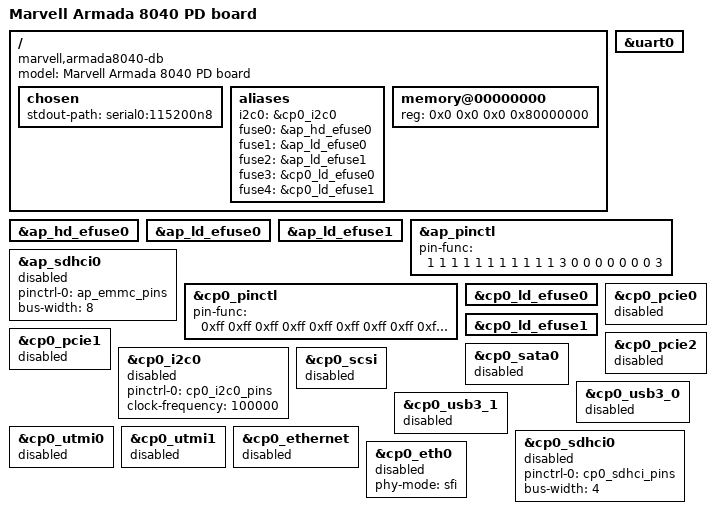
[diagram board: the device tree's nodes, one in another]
/*
 * Copyright (C) 2018 Marvell International Ltd.
 *
 * SPDX-License-Identifier:    GPL-2.0
 * https://spdx.org/licenses
 */

/*
 * Device Tree file for Marvell Armada 8040 Palladium emulation board
 */

#include "armada-80x0-db.dtsi"

/ {
	model = "Marvell Armada 8040 PD board";
	compatible = "marvell,armada8040-db", "marvell,armada8040",
		     "marvell,armada-ap806-quad", "marvell,armada-ap806";

	chosen {
		stdout-path = "serial0:115200n8";
	};

	aliases {
		i2c0 = &cp0_i2c0;
		fuse0 = &ap_hd_efuse0;
		fuse1 = &ap_ld_efuse0;
		fuse2 = &ap_ld_efuse1;
		fuse3 = &cp0_ld_efuse0;
		fuse4 = &cp0_ld_efuse1;
	};

	memory@00000000 {
		device_type = "memory";
		reg = <0x0 0x0 0x0 0x80000000>;
	};


};

/* Accessible over the mini-USB CON9 connector on the main board */
&uart0 {
	status = "okay";
};

&ap_hd_efuse0 {
	status = "okay";
};

&ap_ld_efuse0 {
	status = "okay";
};

&ap_ld_efuse1 {
	status = "okay";
};

&ap_pinctl {
	/* MPP Bus:
	 * SDIO  [0-10]
	 * UART0 [11,19]
	 */
		  /* 0 1 2 3 4 5 6 7 8 9 */
	pin-func = < 1 1 1 1 1 1 1 1 1 1
		     1 3 0 0 0 0 0 0 0 3 >;
};

&ap_sdhci0 {
	pinctrl-names = "default";
	pinctrl-0 = <&ap_emmc_pins>;
	bus-width = <8>;
	status = "disabled";
};

&cp0_pinctl {
	/* MPP Bus:
	 *	[0-31]	= 0xff: Keep default CP0_shared_pins
	 *	[11]	CLKOUT_MPP_11 (out)
	 *	[23]	LINK_RD_IN_CP2CP (in)
	 *	[25]	CLKOUT_MPP_25 (out)
	 *	[29]	AVS_FB_IN_CP2CP (in)
	 *	[32,34]	GE_MDIO/MDC
	 *	[33]	GPIO: GE_INT#/push button/Wake
	 *	[35]	MSS_GPIO[3]: MSS_PWDN
	 *	[36]	MSS_GPIO[5]: MSS_VTT_EN
	 *	[37-38]	I2C0
	 *	[39]	PTP_CLK
	 *	[40-41]	SATA[0/1]_PRESENT_ACTIVEn
	 *	[42-43]	XG_MDC/XG_MDIO (XSMI)
	 *	[44-55]	RGMII1
	 *	[56-62]	SD
	 */
	/*   0    1    2    3    4    5    6    7    8    9 */
	pin-func = < 0xff 0xff 0xff 0xff 0xff 0xff 0xff 0xff 0xff 0xff
		     0xff 0xff 0xff 0xff 0xff 0xff 0xff 0xff 0xff 0xff
		     0xff 0xff 0xff 0xff 0xff 0xff 0xff 0xff 0xff 0xff
		     0xff 0xff 0x7  0x0  0x7  0xa  0xa  0x2  0x2  0x5
		     0x9  0x9  0x8  0x8  0x1  0x1  0x1  0x1  0x1  0x1
		     0x1  0x1  0x1  0x1  0x1  0x1  0xe  0xe  0xe  0xe
		     0xe  0xe  0xe>;
};

&cp0_ld_efuse0 {
	status = "okay";
};

&cp0_ld_efuse1 {
	status = "okay";
};


/* CON6 on CP0 expansion */
&cp0_pcie0 {
	status = "disabled";
};

&cp0_pcie1 {
	status = "disabled";
};

/* CON5 on CP0 expansion */
&cp0_pcie2 {
	status = "disabled";
};

&cp0_i2c0 {
	pinctrl-names = "default";
	pinctrl-0 = <&cp0_i2c0_pins>;
	status = "disabled";
	clock-frequency = <100000>;
};

/* CON4 on CP0 expansion */
&cp0_sata0 {
	status = "disabled";
};

&cp0_scsi {
	status = "disabled";
};

/* CON9 on CP0 expansion */
&cp0_usb3_0 {
	status = "disabled";
};

/* CON10 on CP0 expansion */
&cp0_usb3_1 {
	status = "disabled";
};

&cp0_utmi0 {
	status = "disabled";
};

&cp0_utmi1 {
	status = "disabled";
};

&cp0_sdhci0 {
	pinctrl-names = "default";
	pinctrl-0 = <&cp0_sdhci_pins>;
	bus-width = <4>;
	status = "disabled";
};

&cp0_ethernet {
	status = "disabled";
};


&cp0_eth0 {
        status = "disabled";
        phy-mode = "sfi"; /* lane-2 */
};

